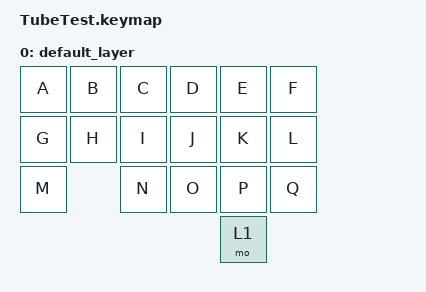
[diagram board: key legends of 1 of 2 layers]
#include <behaviors.dtsi>
#include <dt-bindings/zmk/keys.h>
#include <dt-bindings/zmk/bt.h>

/ {
        keymap {
                compatible = "zmk,keymap";

                default_layer {
                        bindings = <
                          &kp A   &kp B     &kp C     &kp D     &kp E     &kp F
                          &kp G   &kp H     &kp I     &kp J     &kp K     &kp L
                          &kp M             &kp N     &kp O     &kp P     &kp Q
                                                                &mo 1     
                        >;
                };
                bt_layer {
                        bindings = <
                          &kp Z          &kp Y         &kp X            &bt BT_CLR_ALL    &bootloader
                          &bt BT_NXT     &out 0  &out 1
                        >;
                };
        };
};
